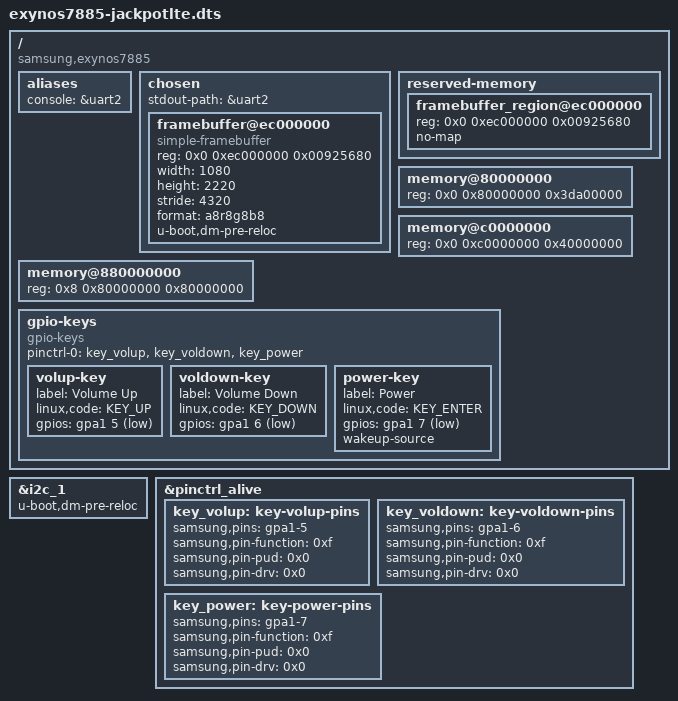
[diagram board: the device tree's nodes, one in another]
// SPDX-License-Identifier: GPL-2.0+
/*
 * Samsung Exynos7885 SoC device tree source
 *
 * Copyright (c) 2023 Dávid Virág (virag.david003@gmail.com)
 */

/dts-v1/;
#include "exynos7885.dtsi"
#include <dt-bindings/gpio/gpio.h>
#include <dt-bindings/input/input.h>
/ {
	compatible = "samsung,exynos7885";

	aliases {
		console = &uart2;
	};

	chosen {
		#address-cells = <2>;
		#size-cells = <1>;
		ranges;

		stdout-path = &uart2;

		framebuffer@ec000000 {
			compatible = "simple-framebuffer";
			reg = <0x0 0xec000000 0x00925680>;
			width = <1080>;
			height = <2220>;
			stride = <4320>;
			format = "a8r8g8b8";
			u-boot,dm-pre-reloc;
		};
	};

	reserved-memory {
		#address-cells = <2>;
		#size-cells = <1>;
		ranges;

		framebuffer_region@ec000000 {
			reg = <0x0 0xec000000 0x00925680>;
			no-map;
		};
	};

	memory@80000000 {
		device_type = "memory";
		reg = <0x0 0x80000000 0x3da00000>;
	};

	memory@c0000000 {
		device_type = "memory";
		reg = <0x0 0xc0000000 0x40000000>;
	};

	memory@880000000 {
		device_type = "memory";
		reg = <0x8 0x80000000 0x80000000>;
	};

	gpio-keys {
		compatible = "gpio-keys";
		pinctrl-names = "default";
		pinctrl-0 = <&key_volup &key_voldown &key_power>;

		volup-key {
			label = "Volume Up";
			linux,code = <KEY_UP>;
			gpios = <&gpa1 5 GPIO_ACTIVE_LOW>;
		};

		voldown-key {
			label = "Volume Down";
			linux,code = <KEY_DOWN>;
			gpios = <&gpa1 6 GPIO_ACTIVE_LOW>;
		};

		power-key {
			label = "Power";
			linux,code = <KEY_ENTER>;
			gpios = <&gpa1 7 GPIO_ACTIVE_LOW>;
			wakeup-source;
		};
	};

};

&i2c_1 {
	status = "okay";
	u-boot,dm-pre-reloc;
};

&pinctrl_alive {
	key_volup: key-volup-pins {
		samsung,pins = "gpa1-5";
		samsung,pin-function = <0xf>;
		samsung,pin-pud = <0x0>;
		samsung,pin-drv = <0x0>;
	};

	key_voldown: key-voldown-pins {
		samsung,pins = "gpa1-6";
		samsung,pin-function = <0xf>;
		samsung,pin-pud = <0x0>;
		samsung,pin-drv = <0x0>;
	};

	key_power: key-power-pins {
		samsung,pins = "gpa1-7";
		samsung,pin-function = <0xf>;
		samsung,pin-pud = <0x0>;
		samsung,pin-drv = <0x0>;
	};
};
